# ATSAML22N18A device description
Architecture: CORTEX-M0PLUS; Family: SAML; Series: SAML22
Registers are 32-bit, read-write, reset 0x0 unless marked. A register's access mark holds for its fields unless they carry their own. Offsets are from the block's base; [hi:lo] are bit positions; {n}, {i} and the like mark numbered series.

## PAC — Peripheral Access Controller
Instances: PAC 0x40000000
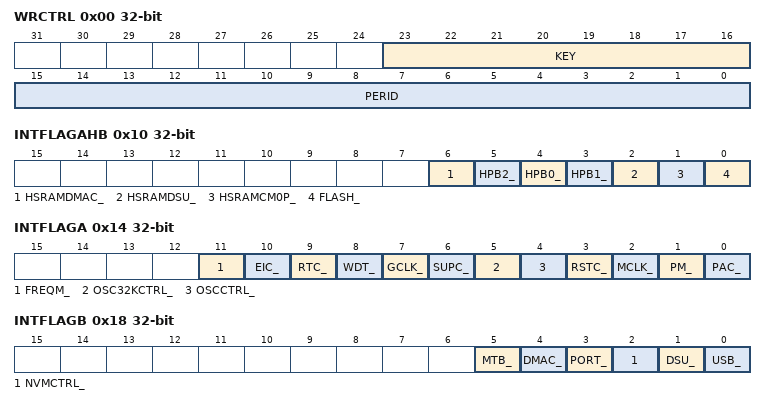
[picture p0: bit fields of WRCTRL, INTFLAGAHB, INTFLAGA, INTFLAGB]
0x00 WRCTRL — Write control
  [23:16] KEY — Peripheral access control key
    0=OFF (No action); 1=CLR (Clear protection); 2=SET (Set protection); 3=SETLCK (Set and lock protection)
  [15:0] PERID — Peripheral identifier
0x04 EVCTRL 8-bit — Event control
  [0] ERREO — Peripheral acess error event output
0x08 INTENCLR 8-bit (atomic clear) — Interrupt enable clear
  [0] ERR — Peripheral access error interrupt disable
0x09 INTENSET 8-bit (atomic set) — Interrupt enable set
  [0] ERR — Peripheral access error interrupt enable
0x10 INTFLAGAHB (atomic clear) — Bridge interrupt flag status
  [6] HSRAMDMAC_, [5] HPB2_, [4] HPB0_, [3] HPB1_, [2] HSRAMDSU_, [1] HSRAMCM0P_, [0] FLASH_
0x14 INTFLAGA (atomic clear) — Peripheral interrupt flag status - Bridge A
  [11] FREQM_, [10] EIC_, [9] RTC_, [8] WDT_, [7] GCLK_, [6] SUPC_, [5] OSC32KCTRL_, [4] OSCCTRL_, [3] RSTC_, [2] MCLK_, [1] PM_, [0] PAC_
0x18 INTFLAGB (atomic clear) — Peripheral interrupt flag status - Bridge B
  [5] MTB_, [4] DMAC_, [3] PORT_, [2] NVMCTRL_, [1] DSU_, [0] USB_
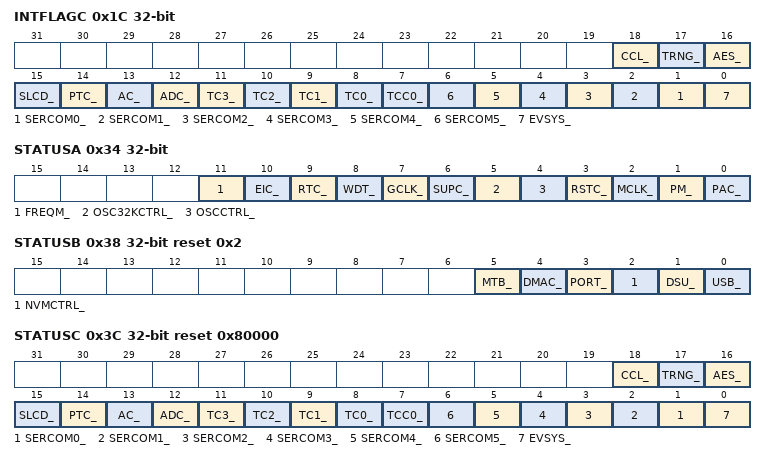
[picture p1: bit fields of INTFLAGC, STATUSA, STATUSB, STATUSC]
0x1C INTFLAGC (atomic clear) — Peripheral interrupt flag status - Bridge C
  [18] CCL_, [17] TRNG_, [16] AES_, [15] SLCD_, [14] PTC_, [13] AC_, [12] ADC_, [n+8] TC{n}_ (n=0..3), [7] TCC0_, [n+1] SERCOM{n}_ (n=0..5), [0] EVSYS_
0x34 STATUSA ro — Peripheral write protection status - Bridge A
  [11] FREQM_ — FREQM APB Protect Enable
  [10] EIC_ — EIC APB Protect Enable
  [9] RTC_ — RTC APB Protect Enable
  [8] WDT_ — WDT APB Protect Enable
  [7] GCLK_ — GCLK APB Protect Enable
  [6] SUPC_ — SUPC APB Protect Enable
  [5] OSC32KCTRL_ — OSC32KCTRL APB Protect Enable
  [4] OSCCTRL_ — OSCCTRL APB Protect Enable
  [3] RSTC_ — RSTC APB Protect Enable
  [2] MCLK_ — MCLK APB Protect Enable
  [1] PM_ — PM APB Protect Enable
  [0] PAC_ — PAC APB Protect Enable
0x38 STATUSB ro reset 0x2 — Peripheral write protection status - Bridge B
  [5] MTB_ — MTB APB Protect Enable
  [4] DMAC_ — DMAC APB Protect Enable
  [3] PORT_ — PORT APB Protect Enable
  [2] NVMCTRL_ — NVMCTRL APB Protect Enable
  [1] DSU_ — DSU APB Protect Enable
  [0] USB_ — USB APB Protect Enable
0x3C STATUSC ro reset 0x80000 — Peripheral write protection status - Bridge C
  [18] CCL_ — CCL APB Protect Enable
  [17] TRNG_ — TRNG APB Protect Enable
  [16] AES_ — AES APB Protect Enable
  [15] SLCD_ — SLCD APB Protect Enable
  [14] PTC_ — PTC APB Protect Enable
  [13] AC_ — AC APB Protect Enable
  [12] ADC_ — ADC APB Protect Enable
  [n+8] TC{n}_ (n=0..3) — TC{n} APB Protect Enable
  [7] TCC0_ — TCC0 APB Protect Enable
  [n+1] SERCOM{n}_ (n=0..5) — SERCOM{n} APB Protect Enable
  [0] EVSYS_ — EVSYS APB Protect Enable

## PM — Power Manager
Instances: PM 0x40000400
0x00 CTRLA 8-bit — Control A
  [2] IORET — I/O Retention
0x01 SLEEPCFG 8-bit reset 0x2 — Sleep Configuration
  [2:0] SLEEPMODE
    2=IDLE (CPU, AHBx, and APBx clocks are OFF); 4=STANDBY (All Clocks are OFF); 5=BACKUP (Only Backup domain is powered ON); 6=OFF (All power domains are powered OFF)
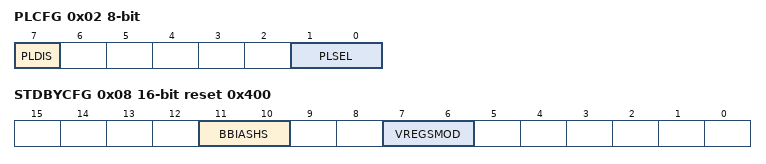
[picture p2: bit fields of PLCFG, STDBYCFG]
0x02 PLCFG 8-bit — Performance Level Configuration
  [7] PLDIS — Performance Level Disable
  [1:0] PLSEL — Performance Level Select
    0=PL0 (Performance Level 0); 1=PL1 (Performance Level 1); 2=PL2 (Performance Level 2)
0x04 INTENCLR 8-bit (atomic clear) — Interrupt Enable Clear
  [0] PLRDY — Performance Level Interrupt Enable
0x05 INTENSET 8-bit (atomic set) — Interrupt Enable Set
  [0] PLRDY — Performance Level Ready interrupt Enable
0x06 INTFLAG 8-bit (atomic clear) — Interrupt Flag Status and Clear
  [0] PLRDY — Performance Level Ready
0x08 STDBYCFG 16-bit reset 0x400 — Standby Configuration
  [11:10] BBIASHS — Back Bias for HMCRAMCHS
    0=RETBB (Retention Back Biasing mode); 1=STDBYBB (Standby Back Biasing mode); 2=STDBYOFF (Standby OFF mode); 3=OFF (Always OFF mode)
  [7:6] VREGSMOD — Voltage Regulator Standby mode
    0=AUTO (Automatic mode); 1=PERFORMANCE (Performance oriented); 2=LP (Low Power oriented)
Value list PM_STDBYCFG__LINKPD: 0=DEFAULT (Power domains are not linked); 1=PD01 (PD0 and PD1 power domains are linked); 2=PD12 (PD1 and PD2 power domains are linked); 3=PD012 (All power domains are linked)
Value list PM_STDBYCFG__PDCFG: 0=DEFAULT (All power domains switching is handled by hardware.); 1=PD0 (PD0 is forced ACTIVE. PD1 and PD2 power domains switching is handled by hardware.); 2=PD01 (PD0 and PD1 are forced ACTIVE. PD2 power domain switching is handled by hardware.); 3=PD012 (All power domains are forced ACTIVE.)

## Notices in the file
Copyright (c) 2018 Microchip Technology Inc.
SPDX-License-Identifier: Apache-2.0
Licensed under the Apache License, Version 2.0 (the "License");
you may not use this file except in compliance with the License.
You may obtain a copy of the License at
http://www.apache.org/licenses/LICENSE-2.0
Unless required by applicable law or agreed to in writing, software
distributed under the License is distributed on an "AS IS" BASIS,
WITHOUT WARRANTIES OR CONDITIONS OF ANY KIND, either express or implied.
See the License for the specific language governing permissions and
limitations under the License.
